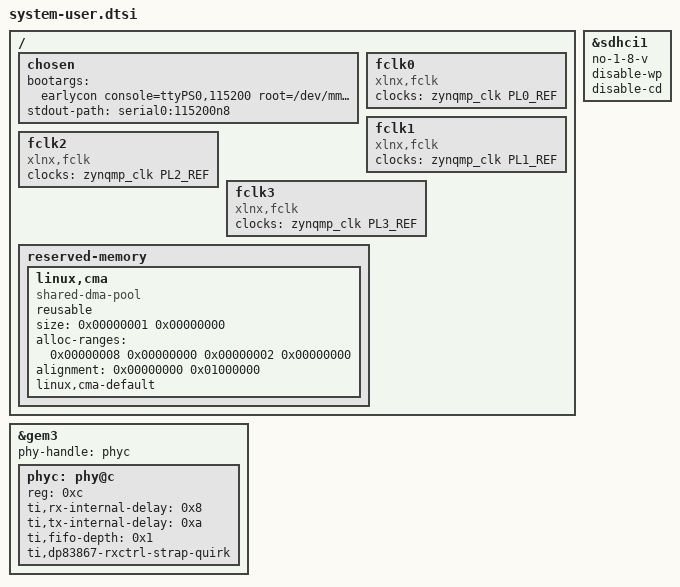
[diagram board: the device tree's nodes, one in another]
/include/ "system-conf.dtsi"

/ {
    chosen {
        bootargs = "earlycon console=ttyPS0,115200 root=/dev/mmcblk0p2 rw rootwait clk_ignore_unused uio_pdrv_genirq.of_id=\"generic-uio\" cma=4096M";
        stdout-path = "serial0:115200n8";
    };

    /* Workaround for AMD/Xilinx fclk management bug */
    fclk0: fclk0 {
        status = "okay";
        compatible = "xlnx,fclk";
        clock-names = "fclk0";
        clocks = <&zynqmp_clk PL0_REF>;
    };
    fclk1: fclk1 {
        status = "okay";
        compatible = "xlnx,fclk";
        clock-names = "fclk1";
        clocks = <&zynqmp_clk PL1_REF>;
    };
    fclk2: fclk2 {
        status = "okay";
        compatible = "xlnx,fclk";
        clock-names = "fclk2";
        clocks = <&zynqmp_clk PL2_REF>;
    };
    fclk3: fclk3 {
        status = "okay";
        compatible = "xlnx,fclk";
        clock-names = "fclk3";
        clocks = <&zynqmp_clk PL3_REF>;
    };

    reserved-memory {
        #address-cells = <2>;
        #size-cells = <2>;
        ranges;

        linux,cma {
            compatible = "shared-dma-pool";
            reusable;

            /* 1. Set Size to 4GB (0x1_0000_0000) */
            size = <0x00000001 0x00000000>;

            /* 2. Increased the window length to 8GB (0x2_0000_0000)
               to accommodate the 4GB allocation request.
               The search range is now from 8GB to 16GB physical address. */
            alloc-ranges = <0x00000008 0x00000000 0x00000002 0x00000000>;

            /* 3. Alignment for large contiguous blocks */
            alignment = <0x00000000 0x01000000>;

            linux,cma-default;
        };
    };
};

&sdhci1 {
    no-1-8-v; /* Standard fix for ZU9/ZU15 level shifters */
    disable-wp;
    disable-cd;
};

&gem3 {
    phy-handle = <&phyc>;
    phyc: phy@c {
        reg = <0xc>;
        ti,rx-internal-delay = <0x8>;
        ti,tx-internal-delay = <0xa>;
        ti,fifo-depth = <0x1>;
        ti,dp83867-rxctrl-strap-quirk;
    };
};
